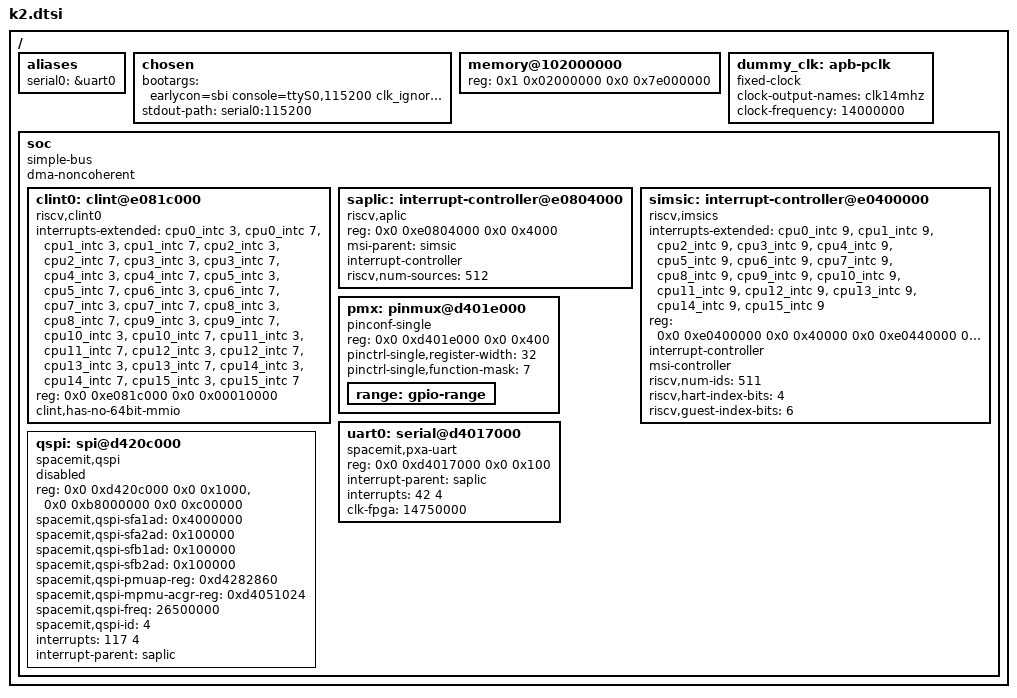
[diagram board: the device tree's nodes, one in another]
// SPDX-License-Identifier: (GPL-2.0 OR MIT)
/* Copyright (c) 2025 Spacemit, Inc */

/dts-v1/;

#include "k2-cpus.dtsi"

/ {
	#address-cells = <2>;
	#size-cells = <2>;

	aliases {
		serial0 = &uart0;
	};

	chosen {
		bootargs = "earlycon=sbi console=ttyS0,115200 clk_ignore_unused nohlt loglevel=8 initcall_debug=1 memblock=debug";
		stdout-path = "serial0:115200";
	};

	memory@102000000 {
		device_type = "memory";
		reg = <0x1 0x02000000 0x0 0x7e000000>;
	};

	dummy_clk: apb-pclk {
		compatible = "fixed-clock";
		#clock-cells = <0x0>;
		clock-output-names = "clk14mhz";
		clock-frequency = <14000000>;
	};

	soc: soc {
		#address-cells = <2>;
		#size-cells = <2>;
		compatible = "simple-bus";
		dma-noncoherent;
		ranges;

		clint0: clint@e081c000 {
			compatible = "riscv,clint0";
			interrupts-extended = <&cpu0_intc  3 &cpu0_intc  7
				&cpu1_intc  3 &cpu1_intc  7
				&cpu2_intc  3 &cpu2_intc  7
				&cpu3_intc  3 &cpu3_intc  7
				&cpu4_intc  3 &cpu4_intc  7
				&cpu5_intc  3 &cpu5_intc  7
				&cpu6_intc  3 &cpu6_intc  7
				&cpu7_intc  3 &cpu7_intc  7
				&cpu8_intc  3 &cpu8_intc  7
				&cpu9_intc  3 &cpu9_intc  7
				&cpu10_intc  3 &cpu10_intc  7
				&cpu11_intc  3 &cpu11_intc  7
				&cpu12_intc  3 &cpu12_intc  7
				&cpu13_intc  3 &cpu13_intc  7
				&cpu14_intc  3 &cpu14_intc  7
				&cpu15_intc  3 &cpu15_intc  7
			>;
			reg = <0x0 0xe081c000 0x0 0x00010000>;
			clint,has-no-64bit-mmio;
		};

		saplic: interrupt-controller@e0804000 {
			compatible = "riscv,aplic";
			/* aplic config */
			reg = <0x0 0xe0804000 0x0 0x4000>;
			msi-parent = <&simsic>;
			#interrupt-cells = <2>;
			interrupt-controller;
			/* the number of wired interrupt sources:512 */
			riscv,num-sources = <512>;
			status = "okay";
		};

		simsic: interrupt-controller@e0400000 {
			compatible = "riscv,imsics";
			interrupts-extended = <&cpu0_intc 9 &cpu1_intc 9
				&cpu2_intc 9 &cpu3_intc 9
				&cpu4_intc 9 &cpu5_intc 9
				&cpu6_intc 9 &cpu7_intc 9
				&cpu8_intc 9 &cpu9_intc 9
				&cpu10_intc 9 &cpu11_intc 9
				&cpu12_intc 9 &cpu13_intc 9
				&cpu14_intc 9 &cpu15_intc 9>;

			reg = <0x0 0xe0400000 0x0 0x40000
				0x0 0xe0440000 0x0 0x40000
				0x0 0xe0480000 0x0 0x40000
				0x0 0xe04c0000 0x0 0x40000
				0x0 0xe0500000 0x0 0x40000
				0x0 0xe0540000 0x0 0x40000
				0x0 0xe0580000 0x0 0x40000
				0x0 0xe05c0000 0x0 0x40000
				0x0 0xe0600000 0x0 0x40000
				0x0 0xe0640000 0x0 0x40000
				0x0 0xe0680000 0x0 0x40000
				0x0 0xe06c0000 0x0 0x40000
				0x0 0xe0700000 0x0 0x40000
				0x0 0xe0740000 0x0 0x40000
				0x0 0xe0780000 0x0 0x40000
				0x0 0xe07c0000 0x0 0x40000
			>;
			interrupt-controller;
			#interrupt-cells = <0>;
			#msi-cells = <0>;
			msi-controller;
			/* Number of interrupt identities:512 */
			riscv,num-ids = <511>;
			/* Number of HART index bits:16 */
			riscv,hart-index-bits = <4>;
			/* Number of guest index bits:7 */
			riscv,guest-index-bits = <6>;
			status = "okay";
		};

		pmx: pinmux@d401e000 {
			compatible = "pinconf-single";
			reg = <0x0 0xd401e000 0x0 0x400>;
			#address-cells = <2>;
			#size-cells = <2>;
			#pinctrl-cells = <1>;
			#gpio-range-cells = <3>;
			ranges;
			pinctrl-single,register-width = <32>;
			pinctrl-single,function-mask = <7>;
			range: gpio-range {
			#pinctrl-single,gpio-range-cells = <3>;
			};
		};

		uart0: serial@d4017000 {
			compatible = "spacemit,pxa-uart";
			reg = <0x0 0xd4017000 0x0 0x100>;
			interrupt-parent = <&saplic>;
			interrupts = <42 4>;
			clk-fpga = <14750000>;
			status = "ok";
		};

		qspi: spi@d420c000 {
			compatible = "spacemit,qspi";
			#address-cells = <1>;
			#size-cells = <0>;
			reg = <0x0 0xd420c000 0x0 0x1000>,
				<0x0 0xb8000000 0x0 0xc00000>;
			reg-names = "qspi-base", "qspi-mmap";
			spacemit,qspi-sfa1ad = <0x4000000>;
			spacemit,qspi-sfa2ad = <0x100000>;
			spacemit,qspi-sfb1ad = <0x100000>;
			spacemit,qspi-sfb2ad = <0x100000>;
			spacemit,qspi-pmuap-reg = <0xd4282860>;
			spacemit,qspi-mpmu-acgr-reg = <0xd4051024>;
			spacemit,qspi-freq = <26500000>;
			spacemit,qspi-id = <4>;
			interrupts = <117 4>;
			interrupt-parent = <&saplic>;
			status = "disabled";
		};
	};
};

